# DDRSS0_CTL_CFG register map
Vendor: Texas Instruments
Registers are 32-bit, read-write, reset 0x0 unless marked. A register's access mark holds for its fields unless they carry their own. Offsets are as the file gives them; [hi:lo] are bit positions; lines under a group give offsets from that group; {n}, {i} and the like mark numbered series.

## DDRSS0_CTL_CFG (part 4 of 5)
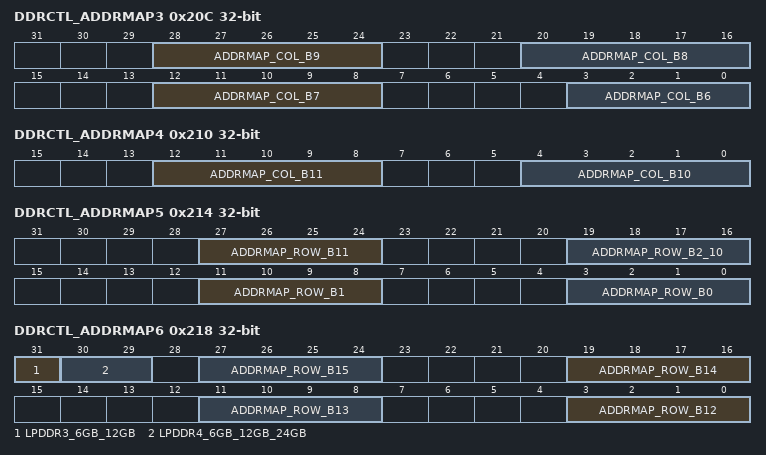
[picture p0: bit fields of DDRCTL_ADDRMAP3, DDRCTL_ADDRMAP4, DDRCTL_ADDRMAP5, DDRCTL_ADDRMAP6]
0x20C DDRCTL_ADDRMAP3 — Address Map Register 3
  [28:24] ADDRMAP_COL_B9 — - Full bus width mode: Selects the HIF address bit used as column address bit 9.- Half bus width mode: Selects the HIF address bit used as column address bit 11 (10 in LPDDR2/LPDDR3 mode). - Quarter bus width mode: Selects the HIF address bit used as column address bit 13 (11 in LPDDR2/LPDDR3 mode). Valid Range: 0 to 7, x, and 31. x indicate a valid value in inline ECC configuration. Internal Base: 9 The selected HIF address bit is determined by adding the internal base to the value of this field. If unused, set to 31 and then this column address bit is set to 0. Note: Per JEDEC DDR2/3/mDDR specification, column address bit 10 is reserved for indicating auto-precharge, and hence no source address bit can be mapped to column address bit 10. In LPDDR2/LPDDR3, there is a dedicated bit for auto-precharge in the CA bus and hence column bit 10 is used. In Inline ECC configuration (MEMC_INLINE_ECC=1) and ECC is enabled (DDRCTL_ECCCFG0.ecc_mode&gt;0), the highest 3 column address bits must map to the highest 3 valid HIF address bits. If column bit 9 is the highest column address bit, it must map to the highest valid HIF address bit. (x = the highest valid HIF address bit - internal base) If column bit 9 is the second highest column address bit, it must map to the second highest valid HIF address bit. (x = the highest valid HIF address bit - 1 - internal base) If column bit 9 is the third highest column address bit, it must map to the third highest valid HIF address bit. (x = the highest valid HIF address bit - 2 - internal base) if it is unused, set to 31. Programming Mode: Static
  [20:16] ADDRMAP_COL_B8 — - Full bus width mode: Selects the HIF address bit used as column address bit 8.- Half bus width mode: Selects the HIF address bit used as column address bit 9. - Quarter bus width mode: Selects the HIF address bit used as column address bit 11 (10 in LPDDR2/LPDDR3 mode). Valid Range: 0 to 7, x, and 31. x indicate a valid value in inline ECC configuration. Internal Base: 8 The selected HIF address bit is determined by adding the internal base to the value of this field. If unused, set to 31 and then this column address bit is set to 0. Note: Per JEDEC DDR2/3/mDDR specification, column address bit 10 is reserved for indicating auto-precharge, and hence no source address bit can be mapped to column address bit 10. In LPDDR2/LPDDR3, there is a dedicated bit for auto-precharge in the CA bus and hence column bit 10 is used. In Inline ECC configuration (MEMC_INLINE_ECC=1) and ECC is enabled (DDRCTL_ECCCFG0.ecc_mode&gt;0), the highest 3 column address bits must map to the highest 3 valid HIF address bits. If column bit 8 is the second highest column address bit, it must map to the second highest valid HIF address bit. (x = the highest valid HIF address bit - 1 - internal base) If column bit 8 is the third highest column address bit, it must map to the third highest valid HIF address bit. (x = the highest valid HIF address bit - 2 - internal base) if it is unused, set to 31. Programming Mode: Static
  [12:8] ADDRMAP_COL_B7 — - Full bus width mode: Selects the HIF address bit used as column address bit 7.- Half bus width mode: Selects the HIF address bit used as column address bit 8. - Quarter bus width mode: Selects the HIF address bit used as column address bit 9. Valid Range: 0 to 7, x, and 31. x indicate a valid value in inline ECC configuration. Internal Base: 7 The selected HIF address bit is determined by adding the internal base to the value of this field. If unused, set to 31 and then this column address bit is set to 0. In Inline ECC configuration (MEMC_INLINE_ECC=1) and ECC is enabled (DDRCTL_ECCCFG0.ecc_mode&gt;0), the highest 3 column address bits must map to the highest 3 valid HIF address bits. If column bit 7 is the third highest column address bit, it must map to the third highest valid HIF address bit. (x = the highest valid HIF address bit - 2 - internal base) if it is unused, set to 31. Programming Mode: Static
  [3:0] ADDRMAP_COL_B6 — - Full bus width mode: Selects the HIF address bit used as column address bit 6.- Half bus width mode: Selects the HIF address bit used as column address bit 7. - Quarter bus width mode: Selects the HIF address bit used as column address bit 8. Valid Range: 0 to 7, and 15 Internal Base: 6 The selected HIF address bit is determined by adding the internal base to the value of this field. If unused, set to 15 and then this column address bit is set to 0. Programming Mode: Static
0x210 DDRCTL_ADDRMAP4 — Address Map Register 4
  [12:8] ADDRMAP_COL_B11 — - Full bus width mode: Selects the HIF address bit used as column address bit 13 (11 in LPDDR2/LPDDR3 mode).- Half bus width mode: Unused. To make it unused, this should be tied to 4'hF. - Quarter bus width mode: Unused. To make it unused, this must be tied to 4'hF. Valid Range: 0 to 7, x, and 31. x indicate a valid value in inline ECC configuration. Internal Base: 11 The selected HIF address bit is determined by adding the internal base to the value of this field. If unused, set to 31 and then this column address bit is set to 0. Note: Per JEDEC DDR2/3/mDDR specification, column address bit 10 is reserved for indicating auto-precharge, and hence no source address bit can be mapped to column address bit 10. In LPDDR2/LPDDR3, there is a dedicated bit for auto-precharge in the CA bus and hence column bit 10 is used. In Inline ECC configuration (MEMC_INLINE_ECC=1) and ECC is enabled (DDRCTL_ECCCFG0.ecc_mode&gt;0), the highest 3 column address bits must map to the highest 3 valid HIF address bits. If column bit 11 is the highest column address bit, it must map to the highest valid HIF address bit. (x = the highest valid HIF address bit - internal base) If column bit 11 is the second highest column address bit, it must map to the second highest valid HIF address bit. (x = the highest valid HIF address bit - 1 - internal base) If column bit 11 is the third highest column address bit, it must map to the third highest valid HIF address bit. (x = the highest valid HIF address bit - 2 - internal base) if it is unused, set to 31. Programming Mode: Static
  [4:0] ADDRMAP_COL_B10 — - Full bus width mode: Selects the HIF address bit used as column address bit 11 (10 in LPDDR2/LPDDR3 mode).- Half bus width mode: Selects the HIF address bit used as column address bit 13 (11 in LPDDR2/LPDDR3 mode). - Quarter bus width mode: UNUSED. To make it unused, this must be tied to 4'hF. Valid Range: 0 to 7, x, and 31. x indicate a valid value in inline ECC configuration. Internal Base: 10 The selected HIF address bit is determined by adding the internal base to the value of this field. If unused, set to 31 and then this column address bit is set to 0. Note: Per JEDEC DDR2/3/mDDR specification, column address bit 10 is reserved for indicating auto-precharge, and hence no source address bit can be mapped to column address bit 10. In LPDDR2/LPDDR3, there is a dedicated bit for auto-precharge in the CA bus and hence column bit 10 is used. In Inline ECC configuration (MEMC_INLINE_ECC=1) and ECC is enabled (DDRCTL_ECCCFG0.ecc_mode&gt;0), the highest 3 column address bits must map to the highest 3 valid HIF address bits. If column bit 10 is the highest column address bit, it must map to the highest valid HIF address bit. (x = the highest valid HIF address bit - internal base) If column bit 10 is the second highest column address bit, it must map to the second highest valid HIF address bit. (x = the highest valid HIF address bit - 1 - internal base) If column bit 10 is the third highest column address bit, it must map to the third highest valid HIF address bit. (x = the highest valid HIF address bit - 2 - internal base) if it is unused, set to 31. Programming Mode: Static
0x214 DDRCTL_ADDRMAP5 — Address Map Register 5
  [27:24] ADDRMAP_ROW_B11 — Selects the HIF address bit used as row address bit 11.Valid Range: 0 to 11, and 15 Internal Base: 17 The selected HIF address bit is determined by adding the internal base to the value of this field. If unused, set to 15 and then row address bit 11 is set to 0. Programming Mode: Static
  [19:16] ADDRMAP_ROW_B2_10 — Selects the HIF address bits used as row address bits 2 to 10.Valid Range: 0 to 11, and 15 Internal Base: 8 (for row address bit 2), 9 (for row address bit 3), 10 (for row address bit 4) etc increasing to 16 (for row address bit 10) The selected HIF address bit for each of the row address bits is determined by adding the internal base to the value of this field. When value 15 is used the values of row address bits 2 to 10 are defined by registers DDRCTL_ADDRMAP9, DDRCTL_ADDRMAP10, DDRCTL_ADDRMAP11. Programming Mode: Static
  [11:8] ADDRMAP_ROW_B1 — Selects the HIF address bits used as row address bit 1.Valid Range: 0 to 11 Internal Base: 7 The selected HIF address bit for each of the row address bits is determined by adding the internal base to the value of this field. Programming Mode: Static
  [3:0] ADDRMAP_ROW_B0 — Selects the HIF address bits used as row address bit 0.Valid Range: 0 to 11 Internal Base: 6 The selected HIF address bit for each of the row address bits is determined by adding the internal base to the value of this field. Programming Mode: Static
0x218 DDRCTL_ADDRMAP6 — Address Map Register 6
  [31] LPDDR3_6GB_12GB — Set this to 1 if there is an LPDDR3 SDRAM 6Gb or 12Gb device in use.- 1 - LPDDR3 SDRAM 6Gb/12Gb device in use. Every address having row[14:13]==2'b11 is considered as invalid - 0 - non-LPDDR3 6Gb/12Gb device in use. All addresses are valid Present only in designs configured to support LPDDR3. Programming Mode: Static
  [30:29] LPDDR4_6GB_12GB_24GB — Indicates what type of LPDDR4 SDRAM device is in use.- 2'b00: No LPDDR4 SDRAM 6Gb/12Gb/24Gb device in use. All addresses are valid - 2'b01: LPDDR4 SDRAM 6Gb device in use. Every address having row[14:13]==2'b11 is considered as invalid - 2'b10: LPDDR4 SDRAM 12Gb device in use. Every address having row[15:14]==2'b11 is considered as invalid - 2'b11: LPDDR4 SDRAM 24Gb device in use. Unsupported Present only in designs configured to support LPDDR4. Programming Mode: Static
  [8n-93:8n-96] ADDRMAP_ROW_B{n} (n=12..15) — Selects the HIF address bit used as row address bit {n}.Valid Range: 0 to 11, and 15 Internal Base: {n+6} The selected HIF address bit is determined by adding the internal base to the value of this field. If unused, set to 15 and then row address bit {n} is set to 0. Programming Mode: Static
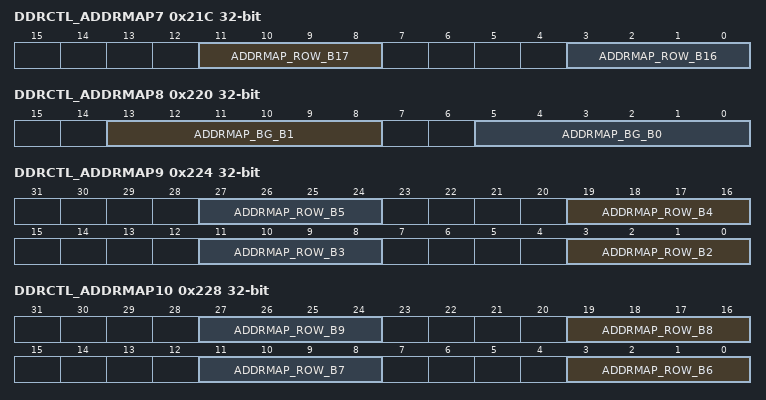
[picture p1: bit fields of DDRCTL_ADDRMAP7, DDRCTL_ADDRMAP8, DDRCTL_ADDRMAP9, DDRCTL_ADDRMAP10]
0x21C DDRCTL_ADDRMAP7 — Address Map Register 7
  [11:8] ADDRMAP_ROW_B17 — Selects the HIF address bit used as row address bit 17.Valid Range: 0 to 11, and 15 Internal Base: 23 The selected HIF address bit is determined by adding the internal base to the value of this field. If unused, set to 15 and then row address bit 17 is set to 0. Programming Mode: Static
  [3:0] ADDRMAP_ROW_B16 — Selects the HIF address bit used as row address bit 16.Valid Range: 0 to 11, and 15 Internal Base: 22 The selected HIF address bit is determined by adding the internal base to the value of this field. If unused, set to 15 and then row address bit 16 is set to 0. Programming Mode: Static
0x220 DDRCTL_ADDRMAP8 — Address Map Register 8
  [13:8] ADDRMAP_BG_B1 — Selects the HIF address bits used as bank group address bit 1.Valid Range: 0 to 32, and 63 Internal Base: 3 The selected HIF address bit for each of the bank group address bits is determined by adding the internal base to the value of this field. If unused, set to 63 and then bank group address bit 1 is set to 0. Programming Mode: Static
  [5:0] ADDRMAP_BG_B0 — Selects the HIF address bits used as bank group address bit 0.Valid Range: 0 to 32 and 63 Internal Base: 2 The selected HIF address bit for each of the bank group address bits is determined by adding the internal base to the value of this field. If unused, set to 63 and then bank group address bit 0 is set to 0. Programming Mode: Static
0x224 DDRCTL_ADDRMAP9 — Address Map Register 9
  [8n-13:8n-16] ADDRMAP_ROW_B{n} (n=2..5) — Selects the HIF address bits used as row address bit {n}.Valid Range: 0 to 11 Internal Base: {n+6} The selected HIF address bit for each of the row address bits is determined by adding the internal base to the value of this field. This register field is used only when DDRCTL_ADDRMAP5.addrmap_row_b2_10 is set to value 15. Programming Mode: Static
0x228 DDRCTL_ADDRMAP10 — Address Map Register 10
  [8n-45:8n-48] ADDRMAP_ROW_B{n} (n=6..9) — Selects the HIF address bits used as row address bit {n}.Valid Range: 0 to 11 Internal Base: {n+6} The selected HIF address bit for each of the row address bits is determined by adding the internal base to the value of this field. This register field is used only when DDRCTL_ADDRMAP5.addrmap_row_b2_10 is set to value 15. Programming Mode: Static
0x22C DDRCTL_ADDRMAP11 — Address Map Register 11
  [3:0] ADDRMAP_ROW_B10 — Selects the HIF address bits used as row address bit 10.Valid Range: 0 to 11 Internal Base: 16 The selected HIF address bit for each of the row address bits is determined by adding the internal base to the value of this field. This register field is used only when DDRCTL_ADDRMAP5.addrmap_row_b2_10 is set to value 15. Programming Mode: Static
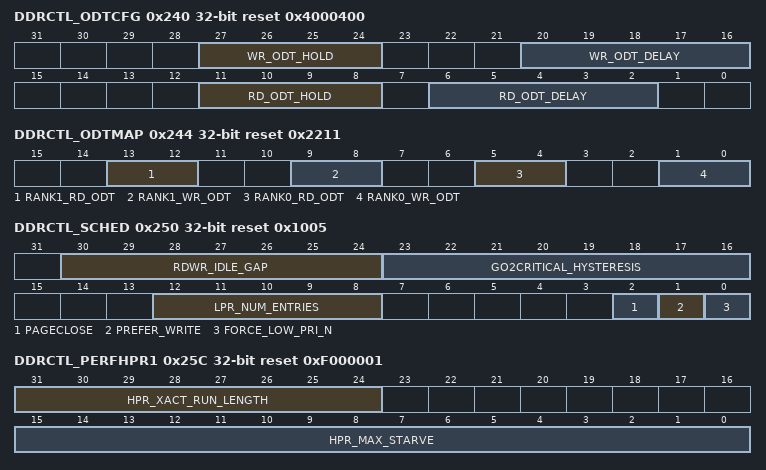
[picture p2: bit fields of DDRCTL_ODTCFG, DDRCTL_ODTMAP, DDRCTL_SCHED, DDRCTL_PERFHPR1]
0x240 DDRCTL_ODTCFG reset 0x4000400 — ODT Configuration Register
  [27:24] WR_ODT_HOLD — DFI PHY clock cycles to hold ODT for a write command.The minimum supported value is 2. Recommended values: DDR2: - BL8: 0x5 (DDR2-400/533/667), 0x6 (DDR2-800), 0x7 (DDR2-1066) - BL4: 0x3 (DDR2-400/533/667), 0x4 (DDR2-800), 0x5 (DDR2-1066) DDR3: - BL8: 0x6 DDR4: - BL8: 5 + WR_PREAMBLE + CRC_MODE WR_PREAMBLE = 1 (1tCK write preamble), 2 (2tCK write preamble) CRC_MODE = 0 (not CRC mode), 1 (CRC mode) LPDDR3: - BL8: 7 + RU(tODTon(max)/tCK) Programming Mode: Quasi-dynamic Group 1 and Group 4
  [20:16] WR_ODT_DELAY — The delay, in DFI PHY clock cycles, from issuing a write command to setting ODT values associated with that command.ODT setting must remain constant for the entire time that DQS is driven by the uMCTL2. Recommended values: DDR2: - CWL + AL - 3 (DDR2-400/533/667), CWL + AL - 4 (DDR2-800), CWL + AL - 5 (DDR2-1066) If (CWL + AL - 3 &lt; 0), uMCTL2 does not support ODT for write operation. DDR3: - 0x0 DDR4: - DDRCTL_DFITMG1.dfi_t_cmd_lat (to adjust for CAL mode) LPDDR3: - WL - 1 - RU(tODTon(max)/tCK)
  [11:8] RD_ODT_HOLD — DFI PHY clock cycles to hold ODT for a read command.The minimum supported value is 2. Recommended values: DDR2: - BL8: 0x6 (not DDR2-1066), 0x7 (DDR2-1066) - BL4: 0x4 (not DDR2-1066), 0x5 (DDR2-1066) DDR3: - BL8 - 0x6 DDR4: - BL8: 5 + RD_PREAMBLE RD_PREAMBLE = 1 (1tCK write preamble), 2 (2tCK write preamble) LPDDR3: - BL8: 5 + RU(tDQSCK(max)/tCK) - RD(tDQSCK(min)/tCK) + RU(tODTon(max)/tCK) Programming Mode: Quasi-dynamic Group 1 and Group 4
  [6:2] RD_ODT_DELAY — The delay, in DFI PHY clock cycles, from issuing a read command to setting ODT values associated with that command.ODT setting must remain constant for the entire time that DQS is driven by the uMCTL2. Recommended values: DDR2: - CL + AL - 4 (not DDR2-1066), CL + AL - 5 (DDR2-1066) If (CL + AL - 4 &lt; 0), uMCTL2 does not support ODT for read operation. DDR3: - CL - CWL DDR4: - CL - CWL - RD_PREAMBLE + WR_PREAMBLE + DDRCTL_DFITMG1.dfi_t_cmd_lat (to adjust for CAL mode) WR_PREAMBLE = 1 (1tCK write preamble), 2 (2tCK write preamble) RD_PREAMBLE = 1 (1tCK write preamble), 2 (2tCK write preamble) If (CL - CWL - RD_PREAMBLE + WR_PREAMBLE) &lt; 0, uMCTL2 does not support ODT for read operation. LPDDR3: - RL + RD(tDQSCK(min)/tCK) - 1 - RU(tODTon(max)/tCK) Programming Mode: Quasi-dynamic Group 1 and Group 4
0x244 DDRCTL_ODTMAP reset 0x2211 — ODT/Rank Map Register
  [13:12] RANK1_RD_ODT — Indicates which remote ODTs must be turned on during a read from rank 1.Each rank has a remote ODT (in the SDRAM) which can be turned on by setting the appropriate bit here. Rank 0 is controlled by the LSB rank 1 is controlled by bit next to the LSB, etc. For each rank, set its bit to 1 to enable its ODT. Present only in configurations that have 2 or more ranks Programming Mode: Static
  [9:8] RANK1_WR_ODT — Indicates which remote ODTs must be turned on during a write to rank 1.Each rank has a remote ODT (in the SDRAM) which can be turned on by setting the appropriate bit here. Rank 0 is controlled by the LSB rank 1 is controlled by bit next to the LSB, etc. For each rank, set its bit to 1 to enable its ODT. Present only in configurations that have 2 or more ranks Programming Mode: Static
  [5:4] RANK0_RD_ODT — Indicates which remote ODTs must be turned on during a read from rank 0.Each rank has a remote ODT (in the SDRAM) which can be turned on by setting the appropriate bit here. Rank 0 is controlled by the LSB rank 1 is controlled by bit next to the LSB, etc. For each rank, set its bit to 1 to enable its ODT. Programming Mode: Static
  [1:0] RANK0_WR_ODT — Indicates which remote ODTs must be turned on during a write to rank 0.Each rank has a remote ODT (in the SDRAM) which can be turned on by setting the appropriate bit here. Rank 0 is controlled by the LSB rank 1 is controlled by bit next to the LSB, etc. For each rank, set its bit to 1 to enable its ODT. Programming Mode: Static
0x250 DDRCTL_SCHED reset 0x1005 — Scheduler Control Register
  [30:24] RDWR_IDLE_GAP — When the preferred transaction store is empty for these many clock cycles, switch to the alternate transaction store if it is non-empty.The read transaction store (both high and low priority) is the default preferred transaction store and the write transaction store is the alternative store. When prefer write over read is set this is reversed. 0x0 is a legal value for this register. When set to 0x0, the transaction store switching will happen immediately when the switching conditions become true. FOR PERFORMANCE ONLY Programming Mode: Static
  [23:16] GO2CRITICAL_HYSTERESIS — UNUSED Programming Mode: Static
  [12:8] LPR_NUM_ENTRIES — Number of entries in the low priority transaction store is this value + 1.(MEMC_NO_OF_ENTRY - (DDRCTL_SCHED.lpr_num_entries + 1)) is the number of entries available for the high priority transaction store. Setting this to maximum value allocates all entries to low priority transaction store. Setting this to 0 allocates 1 entry to low priority transaction store and the rest to high priority transaction store. Note: In ECC configurations, the numbers of write and low priority read credits issued is one less than in the non-ECC case. One entry each is reserved in the write and low-priority read CAMs for storing the RMW requests arising out of single bit error correction RMW operation. Programming Mode: Static
  [2] PAGECLOSE — If true, bank is kept open only while there are page hit transactions available in the CAM to that bank.The last read or write command in the CAM with a bank and page hit will be executed with auto-precharge if DDRCTL_SCHED1.pageclose_timer=0. Even if this register set to 1 and DDRCTL_SCHED1.pageclose_timer is set to 0, explicit precharge (and not auto-precharge) may be issued in some cases where there is a mode switch between Write and Read or between LPR and HPR. The Read and Write commands that are executed as part of the ECC scrub requests are also executed without auto-precharge. If false, the bank remains open until there is a need to close it (to open a different page, or for page timeout or refresh timeout) - also known as open page policy. The open page policy can be overridden by setting the per-command-autopre bit on the HIF interface (hif_cmd_autopre). The pageclose feature provids a midway between Open and Close page policies. FOR PERFORMANCE ONLY. Programming Mode: Quasi-dynamic Group 3
  [1] PREFER_WRITE — If set then the bank selector prefers writes over reads.FOR DEBUG ONLY. Programming Mode: Static
  [0] FORCE_LOW_PRI_N — Active low signal.When asserted ('0'), all incoming transactions are forced to low priority. This implies that all High Priority Read (HPR) and Variable Priority Read commands (VPR) will be treated as Low Priority Read (LPR) commands. On the write side, all Variable Priority Write (VPW) commands will be treated as Normal Priority Write (NPW) commands. Forcing the incoming transactions to low priority implicitly turns off Bypass path for read commands. FOR PERFORMANCE ONLY. Programming Mode: Static
0x254 DDRCTL_SCHED1 — Scheduler Control Register 1
  [7:0] PAGECLOSE_TIMER — This field works in conjunction withDDRCTL_SCHED.pageclose. It only has meaning if DDRCTL_SCHED.pageclose==1. If DDRCTL_SCHED.pageclose==1 and pageclose_timer==0, then an auto-precharge may be scheduled for last read or write command in the CAM with a bank and page hit. Note, sometimes an explicit precharge is scheduled instead of the auto-precharge. See DDRCTL_SCHED.pageclose for details of when this may happen. If DDRCTL_SCHED.pageclose==1 and pageclose_timer&gt;0, then an auto-precharge is not scheduled for last read or write command in the CAM with a bank and page hit. Instead, a timer is started, with pageclose_timer as the initial value. There is a timer on a per bank basis. The timer decrements unless the next read or write in the CAM to a bank is a page hit. It gets reset to pageclose_timer value if the next read or write in the CAM to a bank is a page hit. Once the timer has reached zero, an explcit precharge will be attempted to be scheduled. Programming Mode: Static
0x25C DDRCTL_PERFHPR1 reset 0xF000001 — High Priority Read CAM Register 1
  [31:24] HPR_XACT_RUN_LENGTH — Number of transactions that are serviced once the HPR queue goes critical is the smaller of: - (a) This number - (b) Number of transactions available.Unit: Transaction. FOR PERFORMANCE ONLY. Programming Mode: Quasi-dynamic Group 3
  [15:0] HPR_MAX_STARVE — Number of DFI clocks that the HPR queue can be starved before it goes critical.The minimum valid functional value for this register is 0x1. Programming it to 0x0 will disable the starvation functionality during normal operation, this function should not be disabled as it will cause excessive latencies. FOR PERFORMANCE ONLY. Programming Mode: Quasi-dynamic Group 3
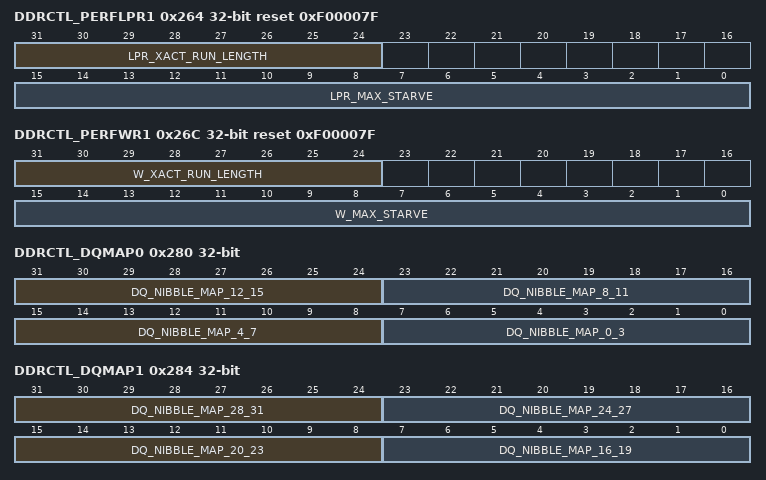
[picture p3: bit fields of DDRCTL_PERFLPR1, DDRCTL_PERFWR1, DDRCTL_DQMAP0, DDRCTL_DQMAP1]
0x264 DDRCTL_PERFLPR1 reset 0xF00007F — Low Priority Read CAM Register 1
  [31:24] LPR_XACT_RUN_LENGTH — Number of transactions that are serviced once the LPR queue goes critical is the smaller of: - (a) This number - (b) Number of transactions available.Unit: Transaction. FOR PERFORMANCE ONLY. Programming Mode: Quasi-dynamic Group 3
  [15:0] LPR_MAX_STARVE — Number of DFI clocks that the LPR queue can be starved before it goes critical.The minimum valid functional value for this register is 0x1. Programming it to 0x0 will disable the starvation functionality during normal operation, this function should not be disabled as it will cause excessive latencies. FOR PERFORMANCE ONLY. Programming Mode: Quasi-dynamic Group 3
0x26C DDRCTL_PERFWR1 reset 0xF00007F — Write CAM Register 1
  [31:24] W_XACT_RUN_LENGTH — Number of transactions that are serviced once the WR queue goes critical is the smaller of: - (a) This number - (b) Number of transactions available.Unit: Transaction. FOR PERFORMANCE ONLY. Programming Mode: Quasi-dynamic Group 3
  [15:0] W_MAX_STARVE — Number of DFI clocks that the WR queue can be starved before it goes critical.The minimum valid functional value for this register is 0x1. Programming it to 0x0 will disable the starvation functionality during normal operation, this function should not be disabled as it will cause excessive latencies. FOR PERFORMANCE ONLY. Programming Mode: Quasi-dynamic Group 3
0x280 DDRCTL_DQMAP0 — DQ Map Register 0
  [31:24] DQ_NIBBLE_MAP_12_15 — DQ nibble map for DQ bits[12-15] Present only in designs configured to support DDR4. Programming Mode: Static
  [23:16] DQ_NIBBLE_MAP_8_11 — DQ nibble map for DQ bits[8-11] Present only in designs configured to support DDR4. Programming Mode: Static
  [15:8] DQ_NIBBLE_MAP_4_7 — DQ nibble map for DQ bits[4-7] Present only in designs configured to support DDR4. Programming Mode: Static
  [7:0] DQ_NIBBLE_MAP_0_3 — DQ nibble map for DQ bits[0-3] Present only in designs configured to support DDR4. Programming Mode: Static
0x284 DDRCTL_DQMAP1 — DQ Map Register 1
  [31:24] DQ_NIBBLE_MAP_28_31 — DQ nibble map for DQ bits[28-31] Present only in designs configured to support DDR4. Programming Mode: Static
  [23:16] DQ_NIBBLE_MAP_24_27 — DQ nibble map for DQ bits[24-27] Present only in designs configured to support DDR4. Programming Mode: Static
  [15:8] DQ_NIBBLE_MAP_20_23 — DQ nibble map for DQ bits[20-23] Present only in designs configured to support DDR4. Programming Mode: Static
  [7:0] DQ_NIBBLE_MAP_16_19 — DQ nibble map for DQ bits[16-19] Present only in designs configured to support DDR4. Programming Mode: Static
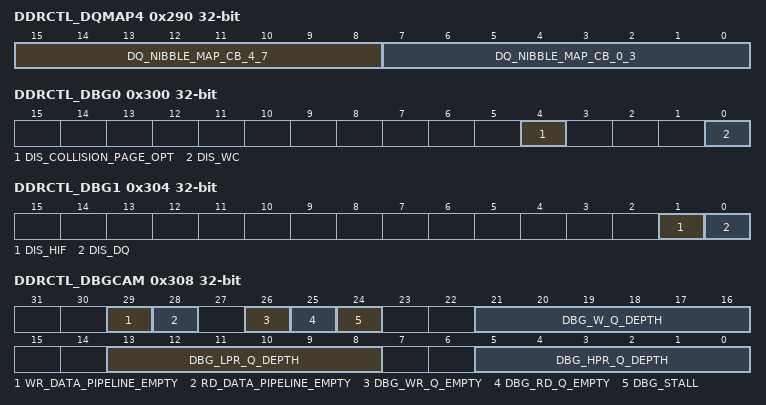
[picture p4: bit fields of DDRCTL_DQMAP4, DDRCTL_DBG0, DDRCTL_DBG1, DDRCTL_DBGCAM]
0x290 DDRCTL_DQMAP4 — DQ Map Register 4
  [15:8] DQ_NIBBLE_MAP_CB_4_7 — DQ nibble map for DIMM ECC check bits[4-7] Present only in designs configured to support DDR4. Programming Mode: Static
  [7:0] DQ_NIBBLE_MAP_CB_0_3 — DQ nibble map for DIMM ECC check bits[0-3] Present only in designs configured to support DDR4. Programming Mode: Static
0x294 DDRCTL_DQMAP5 — DQ Map Register 5
  [0] DIS_DQ_RANK_SWAP — All even ranks have the same DQ mapping controled by DQMAP0-4 register as rank 0. This register provides DQ swap function for all odd ranks to support CRC feature. rank based DQ swapping is: swap bit 0 with 1, swap bit 2 with 3, swap bit 4 with 5 and swap bit 6 with 7. 1: Disable rank based DQ swapping 0: Enable rank based DQ swapping Present only in designs configured to support DDR4. Programming Mode: Static
0x300 DDRCTL_DBG0 — Debug Register 0
  [4] DIS_COLLISION_PAGE_OPT — When this is set to '0', auto-precharge is disabled for the flushed command in a collision case.Collision cases are write followed by read to same address, read followed by write to same address, or write followed by write to same address with DDRCTL_DBG0.dis_wc bit = 1 (where same address comparisons exclude the two address bits representing critical word). FOR DEBUG ONLY. Programming Mode: Static
  [0] DIS_WC — When 1, disable write combine.FOR DEBUG ONLY Programming Mode: Static
0x304 DDRCTL_DBG1 — Debug Register 1
  [1] DIS_HIF — When 1, uMCTL2 asserts the HIF command signal hif_cmd_stall.uMCTL2 will ignore the hif_cmd_valid and all other associated request signals. This bit is intended to be switched on-the-fly. Programming Mode: Dynamic
  [0] DIS_DQ — When 1, uMCTL2 will not de-queue any transactions from the CAM.Bypass is also disabled. All transactions are queued in the CAM. No reads or writes are issued to SDRAM as long as this is asserted. This bit may be used to prevent reads or writes being issued by the uMCTL2, which makes it safe to modify certain register fields associated with reads and writes. After setting this bit, it is strongly recommended to poll DDRCTL_DBGCAM.wr_data_pipeline_empty and DDRCTL_DBGCAM.rd_data_pipeline_empty, before making changes to any registers which affect reads and writes. This will ensure that the relevant logic in the DDRC is idle. This bit is intended to be switched on-the-fly. Programming Mode: Dynamic
0x308 DDRCTL_DBGCAM ro — CAM Debug Register
  [29] WR_DATA_PIPELINE_EMPTY — This bit indicates that the write data pipeline on the DFI interface is empty.This register is intended to be polled at least twice after setting DDRCTL_DBG1.dis_dq, to ensure that all remaining commands/data have completed. Programming Mode: Dynamic
  [28] RD_DATA_PIPELINE_EMPTY — This bit indicates that the read data pipeline on the DFI interface is empty.This register is intended to be polled at least twice after setting DDRCTL_DBG1.dis_dq, to ensure that all remaining commands/data have completed. Programming Mode: Dynamic
  [26] DBG_WR_Q_EMPTY — When 1, all the Write command queues and Write data buffers inside DDRC are empty.This register is to be used for debug purpose. An example use-case scenario: When Controller enters Self-Refresh using the Low-Power entry sequence, Controller is expected to have executed all the commands in its queues and the write and read data drained. Hence this register should be 1 at that time. FOR DEBUG ONLY Programming Mode: Dynamic
  [25] DBG_RD_Q_EMPTY — When 1, all the Read command queues and Read data buffers inside DDRC are empty.This register is to be used for debug purpose. An example use-case scenario: When Controller enters Self-Refresh using the Low-Power entry sequence, Controller is expected to have executed all the commands in its queues and the write and read data drained. Hence this register should be 1 at that time. FOR DEBUG ONLY Programming Mode: Dynamic
  [24] DBG_STALL — Stall FOR DEBUG ONLY Programming Mode: Dynamic
  [21:16] DBG_W_Q_DEPTH — Write queue depth The last entry of WR queue is reserved for ECC SCRUB operation.This entry is not included in the calculation of the queue depth. FOR DEBUG ONLY Programming Mode: Dynamic
  [13:8] DBG_LPR_Q_DEPTH — Low priority read queue depth The last entry of Lpr queue is reserved for ECC SCRUB operation.This entry is not included in the calculation of the queue depth. FOR DEBUG ONLY Programming Mode: Dynamic
  [5:0] DBG_HPR_Q_DEPTH — High priority read queue depth FOR DEBUG ONLY Programming Mode: Dynamic
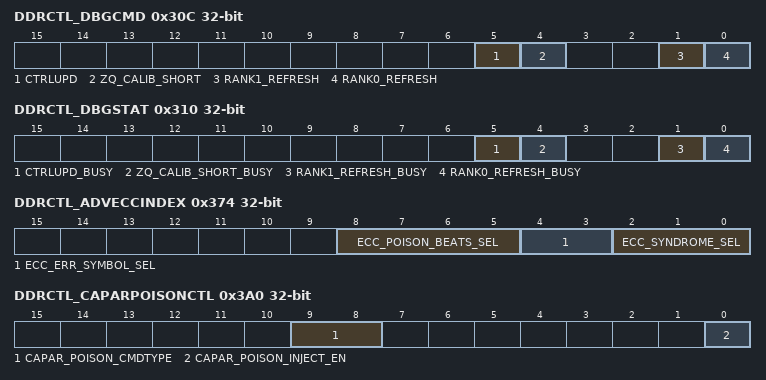
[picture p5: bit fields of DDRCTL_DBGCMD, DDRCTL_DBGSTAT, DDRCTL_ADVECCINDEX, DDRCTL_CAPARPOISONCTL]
0x30C DDRCTL_DBGCMD access not given — Command Debug Register
  [5] CTRLUPD — Setting this register bit to 1 indicates to the uMCTL2 to issue a dfi_ctrlupd_req to the PHY.When this request is stored in the uMCTL2, the bit is automatically cleared. This operation must only be performed when DDRCTL_DFIUPD0.dis_auto_ctrlupd=1. Programming Mode: Dynamic (access W1S)
  [4] ZQ_CALIB_SHORT — Setting this register bit to 1 indicates to the uMCTL2 to issue a ZQCS (ZQ calibration short)/MPC(ZQ calibration) command to the SDRAM.When this request is stored in the uMCTL2, the bit is automatically cleared. This operation can be performed only when DDRCTL_ZQCTL0.dis_auto_zq=1. It is recommended NOT to set this register bit if in Init operating mode. This register bit is ignored when in Self-Refresh(except LPDDR4) and SR-Powerdown(LPDDR4) and Deep power-down operating modes and Maximum Power Saving Mode. Programming Mode: Dynamic (access W1S)
  [1] RANK1_REFRESH — Setting this register bit to 1 indicates to the uMCTL2 to issue a refresh to rank 1.Writing to this bit causes DDRCTL_DBGSTAT.rank1_refresh_busy to be set. When DDRCTL_DBGSTAT.rank1_refresh_busy is cleared, the command has been stored in uMCTL2. For 3DS configuration, refresh is sent to rank index 1. This operation can be performed only when DDRCTL_RFSHCTL3.dis_auto_refresh=1. It is recommended NOT to set this register bit if in Init or Deep power-down operating modes or Maximum Power Saving Mode. Programming Mode: Dynamic (access W1S)
  [0] RANK0_REFRESH — Setting this register bit to 1 indicates to the uMCTL2 to issue a refresh to rank 0.Writing to this bit causes DDRCTL_DBGSTAT.rank0_refresh_busy to be set. When DDRCTL_DBGSTAT.rank0_refresh_busy is cleared, the command has been stored in uMCTL2. For 3DS configuration, refresh is sent to rank index 0. This operation can be performed only when DDRCTL_RFSHCTL3.dis_auto_refresh=1. It is recommended NOT to set this register bit if in Init or Deep power-down operating modes or Maximum Power Saving Mode. Programming Mode: Dynamic (access W1S)
0x310 DDRCTL_DBGSTAT ro — Status Debug Register
  [5] CTRLUPD_BUSY — SoC core may initiate a ctrlupd operation only if this signal is low.This signal goes high in the clock after the uMCTL2 accepts the ctrlupd request. It goes low when the ctrlupd operation is initiated in the uMCTL2. It is recommended not to perform ctrlupd operations when this signal is high. - 0 - Indicates that the SoC core can initiate a ctrlupd operation - 1 - Indicates that ctrlupd operation has not been initiated yet in the uMCTL2 Programming Mode: Dynamic
  [4] ZQ_CALIB_SHORT_BUSY — SoC core may initiate a ZQCS (ZQ calibration short) operation only if this signal is low.This signal goes high in the clock after the uMCTL2 accepts the ZQCS request. It goes low when the ZQCS operation is initiated in the uMCTL2. It is recommended not to perform ZQCS operations when this signal is high. - 0 - Indicates that the SoC core can initiate a ZQCS operation - 1 - Indicates that ZQCS operation has not been initiated yet in the uMCTL2 Programming Mode: Dynamic
  [1] RANK1_REFRESH_BUSY — SoC core may initiate a rank1_refresh operation (refresh operation to rank 1) only if this signal is low.This signal goes high in the clock after DDRCTL_DBGCMD.rank1_refresh is set to one. It goes low when the rank1_refresh operation is stored in the uMCTL2. It is recommended not to perform rank1_refresh operations when this signal is high. - 0 - Indicates that the SoC core can initiate a rank1_refresh operation - 1 - Indicates that rank1_refresh operation has not been stored yet in the uMCTL2 Programming Mode: Dynamic
  [0] RANK0_REFRESH_BUSY — SoC core may initiate a rank0_refresh operation (refresh operation to rank 0) only if this signal is low.This signal goes high in the clock after DDRCTL_DBGCMD.rank0_refresh is set to one. It goes low when the rank0_refresh operation is stored in the uMCTL2. It is recommended not to perform rank0_refresh operations when this signal is high. - 0 - Indicates that the SoC core can initiate a rank0_refresh operation - 1 - Indicates that rank0_refresh operation has not been stored yet in the uMCTL2 Programming Mode: Dynamic
0x320 DDRCTL_SWCTL reset 0x1 — Software Register Programming Control Enable
  [0] SW_DONE — Enable quasi-dynamic register programming outside reset.Program register to 0 to enable quasi-dynamic programming. Set back register to 1 once programming is done. Programming Mode: Dynamic
0x324 DDRCTL_SWSTAT ro reset 0x1 — Software Register Programming Control Status
  [0] SW_DONE_ACK — Register programming done.This register is the echo of DDRCTL_SWCTL.sw_done. Wait for sw_done value 1 to propagate to sw_done_ack at the end of the programming sequence to ensure that the correct registers values are propagated to the destination clock domains. Programming Mode: Static
0x374 DDRCTL_ADVECCINDEX — Advanced ECC Index Register
  [8:5] ECC_POISON_BEATS_SEL — Selector of which DRAM beat's poison pattern will be set byDDRCTL_ECCPOISONPAT0/1/2 registers. For frequency ratio 1:1 mode, 2 DRAM beats can be poisoned. Set ecc_poison_beats_sel to 0 and given DDRCTL_ECCPOISONPAT0/1/2 to set 1st beat's poison pattern set ecc_poison_beats_sel to 1 and given DDRCTL_ECCPOISONPAT0/1/2 to set 2nd beat's poison pattern. For frequency ratio 1:2 mode, 4 DRAM beats can be poisoned. Set ecc_poison_beats_sel from 0~3 to set 1st to 4th beat's poison pattern. The other value is reserved. Programming Mode: Quasi-dynamic Group 1
  [4:3] ECC_ERR_SYMBOL_SEL — Selector of which error symbol's status output to ADVECCSTAT.advecc_err_symbol_pos and advecc_err_symbol_bits.The default is first error symbol. The value should be less than ADVECCSTAT.advecc_num_err_symbol. Programming Mode: Quasi-dynamic Group 1
  [2:0] ECC_SYNDROME_SEL — Selector of which DRAM beat data output toDDRCTL_ECCCSYN0/1/2 as well as ECCUCSYN. In Advanced ECC, the syndrome consist of number of DRAM beats. This register select which beats of data will be output to DDRCTL_ECCCSYN0/1/2 and ECCUCSYN0/1/2 registers. Programming Mode: Quasi-dynamic Group 1
0x37C DDRCTL_ECCPOISONPAT0 — ECC Poison Pattern 0 Register
  [31:0] ECC_POISON_DATA_31_0 — Poison pattern for DRAM data[31:0].Only bit is set to 1 indicate poison (invert) corresponding DRAM bit. It is indirect register. Selector is DDRCTL_ADVECCINDEX.ecc_poison_beats_sel. Programming Mode: Static
0x384 DDRCTL_ECCPOISONPAT2 — ECC Poison Pattern 2 Register
  [7:0] ECC_POISON_DATA_71_64 — Poison pattern for DRAM data[71:64]. Only bit is set to 1 indicate poison (invert) corresponding DRAM bit. It is indirect register. Selector is DDRCTL_ADVECCINDEX.ecc_poison_beats_sel. Programming Mode: Static
0x3A0 DDRCTL_CAPARPOISONCTL — CA parity poison contrl Register
  [9:8] CAPAR_POISON_CMDTYPE — Command type to be poisoned.- 0 - Write or Read command - 1 - Write command - 2 - Read command - 3 - Reserved Programming Mode: Dynamic
  [0] CAPAR_POISON_INJECT_EN — Setting this register bit to 1 triggers the CA parity poisoning.Once parity is poisoned to a command which is specified by DDRCTL_CAPARPOISONCTL.capar_poison_cmd_type, the CA parity poisoning is completed automatically and DDRCTL_CAPARPOISONSTAT.capar_poison_complete becomes 1. Please make sure that DDRCTL_CAPARPOISONSTAT.capar_poison_complete==0 before writing this register to 1. This feature only supports DDR4 SDRAM. Programming Mode: Dynamic
0x3A4 DDRCTL_CAPARPOISONSTAT ro — CA parity poison status Register
  [0] CAPAR_POISON_COMPLETE — Indicates CA parity poisoning operation is done.- 0 - CA parity poisoning is not completed - 1 - CA parity poisoning is completed Programming Mode: Dynamic
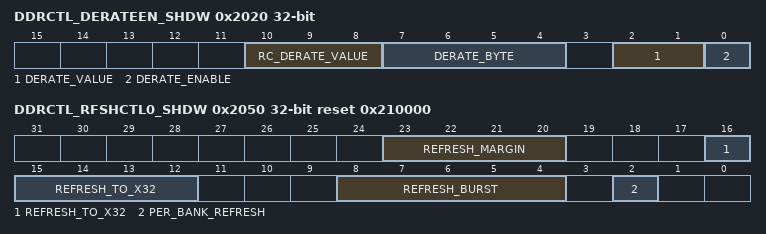
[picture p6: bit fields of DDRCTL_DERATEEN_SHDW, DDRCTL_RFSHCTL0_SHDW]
0x2020 DDRCTL_DERATEEN_SHDW — [FREQ1] Temperature Derate Enable Register
  [10:8] RC_DERATE_VALUE — Derate value of tRC for LPDDR4 - 0 - Derating uses +1. - 1 - Derating uses +2. - 2 - Derating uses +3. - 3 - Derating uses +4. Present only in designs configured to support LPDDR4. The required number of cycles for derating can be determined by dividing 3.75ns by the core_ddrc_core_clk period, and rounding up the next integer. Programming Mode: Quasi-dynamic Group 2 and Group 4
  [7:4] DERATE_BYTE — Derate byte Present only in designs configured to support LPDDR2/LPDDR3/LPDDR4 Indicates which byte of the MRR data is used for derating.The maximum valid value depends on MEMC_DRAM_TOTAL_DATA_WIDTH. Programming Mode: Static
  [2:1] DERATE_VALUE — Derate value -0 - Derating uses +1. - 1 - Derating uses +2. Present only in designs configured to support LPDDR2/LPDDR3/LPDDR4 Set to 0 for all LPDDR2 speed grades as derating value of +1.875 ns is less than a core_ddrc_core_clk period. For LPDDR3/4, if the period of core_ddrc_core_clk is less than 1.875ns, this register field should be set to 1 otherwise it should be set to 0. Programming Mode: Quasi-dynamic Group 2 and Group 4
  [0] DERATE_ENABLE — Enables derating -0 - Timing parameter derating is disabled - 1 - Timing parameter derating is enabled using MR4 read value. Present only in designs configured to support LPDDR2/LPDDR3/LPDDR4 This field must be set to '0' for non-LPDDR2/LPDDR3/LPDDR4 mode. Programming Mode: Dynamic
0x2024 DDRCTL_DERATEINT_SHDW reset 0x800000 — [FREQ1] Temperature Derate Interval Register
  [31:0] MR4_READ_INTERVAL — Interval between two MR4 reads, used to derate the timing parameters.Present only in designs configured to support LPDDR2/LPDDR3/LPDDR4. This register must not be set to zero. Unit: DFI clock cycle. Programming Mode: Static
0x2050 DDRCTL_RFSHCTL0_SHDW reset 0x210000 — [FREQ1] Refresh Control Register 0
  [23:20] REFRESH_MARGIN — Threshold value in number of DFI clock cycles before the critical refresh or page timer expires.A critical refresh is to be issued before this threshold is reached. It is recommended that this not be changed from the default value, currently shown as 0x2. It must always be less than internally used t_rfc_nom_x32. Note that, in LPDDR2/LPDDR3/LPDDR4, internally used t_rfc_nom_x32 may be equal to DDRCTL_RFSHTMG.t_rfc_nom_x32&gt;&gt;2 if derating is enabled (DDRCTL_DERATEEN.derate_enable=1). Otherwise, internally used t_rfc_nom_x32 will be equal to DDRCTL_RFSHTMG.t_rfc_nom_x32. Unit: Multiples of 32 DFI clocks. Programming Mode: Dynamic - Refresh Related
  [16:12] REFRESH_TO_X32 — If the refresh timer (tRFCnom, also known as tREFI) has expired at least once, but it has not expired (DDRCTL_RFSHCTL0.refresh_burst+1) times yet, then a speculative refresh may be performed. A speculative refresh is a refresh performed at a time when refresh would be useful, but before it is absolutely required. When the SDRAM bus is idle for a period of time determined by this DDRCTL_RFSHCTL0.refresh_to_x32 and the refresh timer has expired at least once since the last refresh, then a speculative refresh is performed. Speculative refreshes continues successively until there are no refreshes pending or until new reads or writes are issued to the uMCTL2. FOR PERFORMANCE ONLY. Unit: Multiples of 32 DFI clocks. Programming Mode: Dynamic - Refresh Related
  [8:4] REFRESH_BURST — The programmed value + 1 is the number of refresh timeouts that is allowed to accumulate before traffic is blocked and the refreshes are forced to execute.Closing pages to perform a refresh is a one-time penalty that must be paid for each group of refreshes. Therefore, performing refreshes in a burst reduces the per-refresh penalty of these page closings. Higher numbers for RFSHCTL.refresh_burst slightly increases utilization lower numbers decreases the worst-case latency associated with refreshes. - 0 - single refresh - 1 - burst-of-2 refresh - 7 - burst-of-8 refresh For information on burst refresh feature refer to section 3.9 of DDR2 JEDEC specification - JESD79-2F.pdf. For DDR2/3, the refresh is always per-rank and not per-bank. The rank refresh can be accumulated over 8*tREFI cycles using the burst refresh feature. In DDR4 mode, according to Fine Granularity feature, 8 refreshes can be postponed in 1X mode, 16 refreshes in 2X mode and 32 refreshes in 4X mode. If using PHY-initiated updates, care must be taken in the setting of DDRCTL_RFSHCTL0.refresh_burst, to ensure that tRFCmax is not violated due to a PHY-initiated update occurring shortly before a refresh burst was due. In this situation, the refresh burst will be delayed until the PHY-initiated update is complete. Programming Mode: Dynamic - Refresh Related
  [2] PER_BANK_REFRESH — -1 - Per bank refresh - 0 - All bank refresh. Per bank refresh allows traffic to flow to other banks. Per bank refresh is not supported by all LPDDR2 devices but should be supported by all LPDDR3/LPDDR4 devices. Present only in designs configured to support LPDDR2/LPDDR3/LPDDR4 Programming Mode: Static
